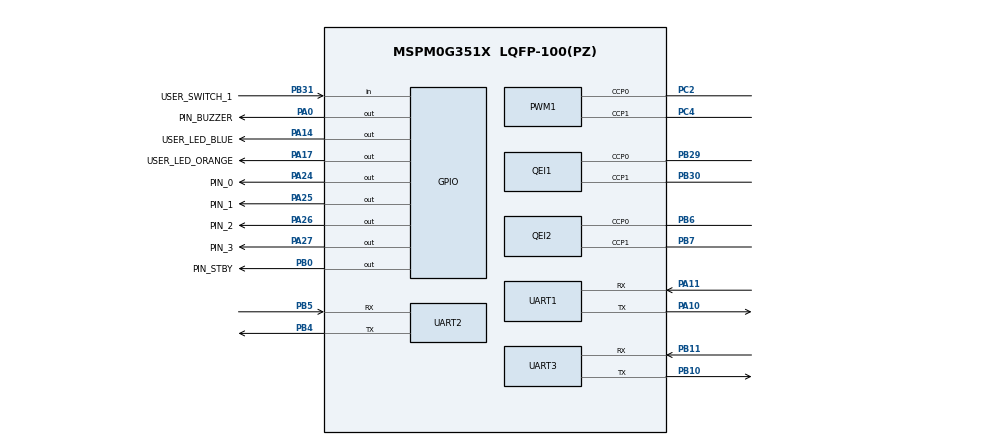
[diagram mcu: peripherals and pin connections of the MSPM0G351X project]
/**
 * @cliArgs --device "MSPM0G351X" --part "Default" --package "LQFP-100(PZ)" --product "mspm0_sdk@2.04.00.06"
 * @versions {"tool":"1.23.1+4034"}
 */

/**
 * Import the modules used in this configuration.
 */
const GPIO   = scripting.addModule("/ti/driverlib/GPIO", {}, false);
const GPIO1  = GPIO.addInstance();
const GPIO2  = GPIO.addInstance();
const GPIO3  = GPIO.addInstance();
const GPIO4  = GPIO.addInstance();
const GPIO5  = GPIO.addInstance();
const GPIO6  = GPIO.addInstance();
const GPIO7  = GPIO.addInstance();
const GPIO8  = GPIO.addInstance();
const PWM    = scripting.addModule("/ti/driverlib/PWM", {}, false);
const PWM1   = PWM.addInstance();
const QEI    = scripting.addModule("/ti/driverlib/QEI", {}, false);
const QEI1   = QEI.addInstance();
const QEI2   = QEI.addInstance();
const SYSCTL = scripting.addModule("/ti/driverlib/SYSCTL");
const UART   = scripting.addModule("/ti/driverlib/UART", {}, false);
const UART1  = UART.addInstance();
const UART2  = UART.addInstance();
const UART3  = UART.addInstance();

/**
 * Write custom configuration values to the imported modules.
 */
GPIO1.$name                         = "GPIO_LEDS";
GPIO1.port                          = "PORTA";
GPIO1.associatedPins.create(2);
GPIO1.associatedPins[0].$name       = "USER_LED_BLUE";
GPIO1.associatedPins[0].assignedPin = "14";
GPIO1.associatedPins[0].pin.$assign = "PA14";
GPIO1.associatedPins[1].$name       = "USER_LED_ORANGE";
GPIO1.associatedPins[1].assignedPin = "17";
GPIO1.associatedPins[1].pin.$assign = "PA17";

const Board = scripting.addModule("/ti/driverlib/Board", {}, false);

GPIO2.$name                              = "GPIO_SWITCHES";
GPIO2.port                               = "PORTB";
GPIO2.associatedPins[0].$name            = "USER_SWITCH_1";
GPIO2.associatedPins[0].direction        = "INPUT";
GPIO2.associatedPins[0].internalResistor = "PULL_UP";
GPIO2.associatedPins[0].assignedPin      = "31";
GPIO2.associatedPins[0].pin.$assign      = "PB31";

GPIO3.$name                   = "AIN1";
GPIO3.associatedPins[0].$name = "PIN_0";
GPIO3.associatedPins[0].pin.$assign = "PA24";

GPIO4.$name                   = "AIN2";
GPIO4.associatedPins[0].$name = "PIN_1";
GPIO4.associatedPins[0].pin.$assign = "PA25";

GPIO5.$name                   = "BIN1";
GPIO5.associatedPins[0].$name = "PIN_2";
GPIO5.associatedPins[0].pin.$assign = "PA26";

GPIO6.$name                   = "BIN2";
GPIO6.associatedPins[0].$name = "PIN_3";
GPIO6.associatedPins[0].pin.$assign = "PA27";

GPIO7.$name                   = "STBY";
GPIO7.associatedPins[0].$name = "PIN_STBY";
GPIO7.associatedPins[0].pin.$assign = "PB0";

GPIO8.$name                   = "GPIO_BUZZER";
GPIO8.associatedPins[0].$name = "PIN_BUZZER";
GPIO8.associatedPins[0].pin.$assign = "PA0";

PWM1.$name                      = "PWM_0";
PWM1.peripheral.ccp0Pin.$assign = "PC2";
PWM1.peripheral.ccp1Pin.$assign = "PC4";
PWM1.PWM_CHANNEL_0.$name        = "ti_driverlib_pwm_PWMTimerCC0";
PWM1.PWM_CHANNEL_1.$name        = "ti_driverlib_pwm_PWMTimerCC1";
PWM1.ccp0PinConfig.$name        = "ti_driverlib_gpio_GPIOPinGeneric6";
PWM1.ccp1PinConfig.$name        = "ti_driverlib_gpio_GPIOPinGeneric7";

QEI1.$name                              = "QEI_Left";
QEI1.peripheral.$assign                 = "TIMG9";
QEI1.peripheral.ccp0Pin.$assign         = "PB29";
QEI1.peripheral.ccp1Pin.$assign         = "PB30";
QEI1.ccp0PinConfig.$name                = "ti_driverlib_gpio_GPIOPinGeneric2";
QEI1.ccp0PinConfig.hideOutputInversion  = scripting.forceWrite(false);
QEI1.ccp0PinConfig.onlyInternalResistor = scripting.forceWrite(false);
QEI1.ccp0PinConfig.passedPeripheralType = scripting.forceWrite("Digital");
QEI1.ccp0PinConfig.internalResistor     = "PULL_UP";
QEI1.ccp1PinConfig.$name                = "ti_driverlib_gpio_GPIOPinGeneric3";
QEI1.ccp1PinConfig.hideOutputInversion  = scripting.forceWrite(false);
QEI1.ccp1PinConfig.onlyInternalResistor = scripting.forceWrite(false);
QEI1.ccp1PinConfig.passedPeripheralType = scripting.forceWrite("Digital");
QEI1.ccp1PinConfig.internalResistor     = "PULL_UP";

QEI2.$name                              = "QEI_Right";
QEI2.peripheral.ccp0Pin.$assign         = "PB6";
QEI2.peripheral.ccp1Pin.$assign         = "PB7";
QEI2.ccp0PinConfig.$name                = "ti_driverlib_gpio_GPIOPinGeneric4";
QEI2.ccp0PinConfig.hideOutputInversion  = scripting.forceWrite(false);
QEI2.ccp0PinConfig.onlyInternalResistor = scripting.forceWrite(false);
QEI2.ccp0PinConfig.passedPeripheralType = scripting.forceWrite("Digital");
QEI2.ccp0PinConfig.internalResistor     = "PULL_UP";
QEI2.ccp1PinConfig.$name                = "ti_driverlib_gpio_GPIOPinGeneric5";
QEI2.ccp1PinConfig.hideOutputInversion  = scripting.forceWrite(false);
QEI2.ccp1PinConfig.onlyInternalResistor = scripting.forceWrite(false);
QEI2.ccp1PinConfig.passedPeripheralType = scripting.forceWrite("Digital");
QEI2.ccp1PinConfig.internalResistor     = "PULL_UP";

SYSCTL.forceDefaultClkConfig = true;
SYSCTL.clockTreeEn           = true;

UART1.$name                      = "UART_0";
UART1.targetBaudRate             = 115200;
UART1.enabledInterrupts          = ["RX"];
UART1.enabledDMARXTriggers       = "DL_UART_DMA_INTERRUPT_RX";
UART1.enabledDMATXTriggers       = "DL_UART_DMA_INTERRUPT_TX";
UART1.peripheral.rxPin.$assign   = "PA11";
UART1.peripheral.txPin.$assign   = "PA10";
UART1.txPinConfig.$name          = "ti_driverlib_gpio_GPIOPinGeneric0";
UART1.rxPinConfig.$name          = "ti_driverlib_gpio_GPIOPinGeneric1";
UART1.DMA_CHANNEL_RX.$name       = "DMA_CH0";
UART1.DMA_CHANNEL_TX.$name       = "DMA_CH1";
UART1.DMA_CHANNEL_TX.addressMode = "b2f";
UART1.DMA_CHANNEL_TX.srcLength   = "BYTE";
UART1.DMA_CHANNEL_TX.dstLength   = "BYTE";

UART2.$name                      = "UART_1";
UART2.targetBaudRate             = 115200;
UART2.enabledInterrupts          = ["RX"];
UART2.enabledDMARXTriggers       = "DL_UART_DMA_INTERRUPT_RX";
UART2.enabledDMATXTriggers       = "DL_UART_DMA_INTERRUPT_TX";
UART2.peripheral.rxPin.$assign   = "PB5";
UART2.peripheral.txPin.$assign   = "PB4";
UART2.txPinConfig.$name          = "ti_driverlib_gpio_GPIOPinGeneric8";
UART2.rxPinConfig.$name          = "ti_driverlib_gpio_GPIOPinGeneric9";
UART2.DMA_CHANNEL_RX.$name       = "DMA_CH2";
UART2.DMA_CHANNEL_TX.$name       = "DMA_CH3";
UART2.DMA_CHANNEL_TX.addressMode = "b2f";
UART2.DMA_CHANNEL_TX.srcLength   = "BYTE";
UART2.DMA_CHANNEL_TX.dstLength   = "BYTE";

UART3.$name                      = "UART_2";
UART3.targetBaudRate             = 115200;
UART3.enabledInterrupts          = ["RX"];
UART3.enabledDMARXTriggers       = "DL_UART_DMA_INTERRUPT_RX";
UART3.enabledDMATXTriggers       = "DL_UART_DMA_INTERRUPT_TX";
UART3.peripheral.rxPin.$assign   = "PB11";
UART3.peripheral.txPin.$assign   = "PB10";
UART3.txPinConfig.$name          = "ti_driverlib_gpio_GPIOPinGeneric10";
UART3.rxPinConfig.$name          = "ti_driverlib_gpio_GPIOPinGeneric11";
UART3.DMA_CHANNEL_RX.$name       = "DMA_CH4";
UART3.DMA_CHANNEL_TX.$name       = "DMA_CH5";
UART3.DMA_CHANNEL_TX.addressMode = "b2f";
UART3.DMA_CHANNEL_TX.srcLength   = "BYTE";
UART3.DMA_CHANNEL_TX.dstLength   = "BYTE";

/**
 * Pinmux solution for unlocked pins/peripherals. This ensures that minor changes to the automatic solver in a future
 * version of the tool will not impact the pinmux you originally saw.  These lines can be completely deleted in order to
 * re-solve from scratch.
 */
Board.peripheral.$suggestSolution                = "DEBUGSS";
Board.peripheral.swclkPin.$suggestSolution       = "PA20";
Board.peripheral.swdioPin.$suggestSolution       = "PA19";
PWM1.peripheral.$suggestSolution                 = "TIMA0";
QEI2.peripheral.$suggestSolution                 = "TIMG8";
UART1.peripheral.$suggestSolution                = "UART0";
UART1.DMA_CHANNEL_RX.peripheral.$suggestSolution = "DMA_CH1";
UART1.DMA_CHANNEL_TX.peripheral.$suggestSolution = "DMA_CH0";
